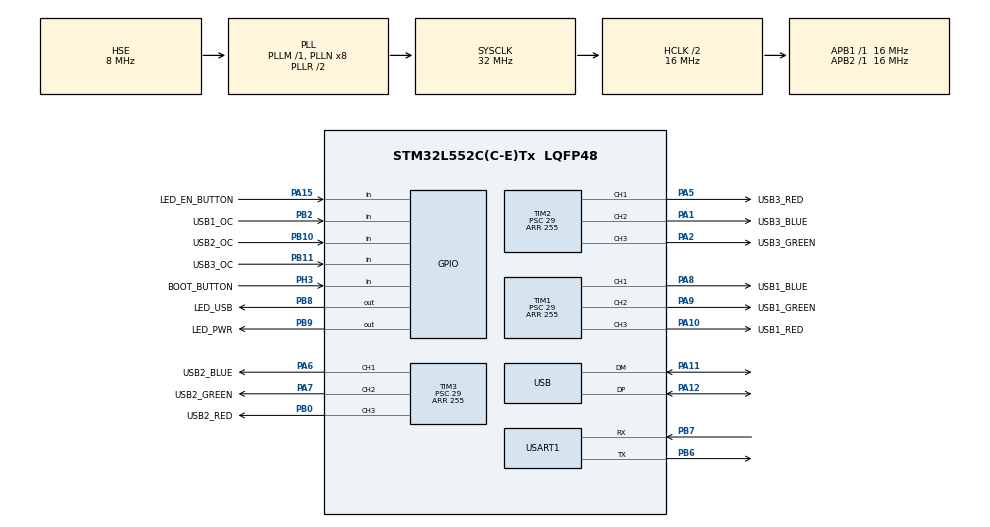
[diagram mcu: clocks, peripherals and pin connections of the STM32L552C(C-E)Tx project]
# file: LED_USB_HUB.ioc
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Mcu.Family=STM32L5
Mcu.Name=STM32L552C(C-E)Tx
Mcu.Package=LQFP48
NVIC.PriorityGroup=NVIC_PRIORITYGROUP_3
NVIC.TIM7_IRQn=true\:7\:0\:false\:false\:true\:false\:true\:true
NVIC.TimeBase=TIM7_IRQn
NVIC.TimeBaseIP=TIM7
PA1.GPIO_Label=USB3_BLUE
PA1.Signal=S_TIM2_CH2
PA10.GPIO_Label=USB1_RED
PA10.Signal=S_TIM1_CH3
PA11.Mode=Device
PA11.Signal=USB_DM
PA12.Mode=Device
PA12.Signal=USB_DP
PA13\ (JTMS/SWDIO).GPIO_Label=SWDIO
PA13\ (JTMS/SWDIO).Mode=Serial_Wire
PA13\ (JTMS/SWDIO).Signal=DEBUG_JTMS-SWDIO
PA14\ (JTCK/SWCLK).GPIO_Label=SWCLK
PA14\ (JTCK/SWCLK).Mode=Serial_Wire
PA14\ (JTCK/SWCLK).Signal=DEBUG_JTCK-SWCLK
PA15\ (JTDI).GPIO_Label=LED_EN_BUTTON
PA15\ (JTDI).Signal=GPIO_Input
PA2.GPIO_Label=USB3_GREEN
PA2.Signal=S_TIM2_CH3
PA5.GPIO_Label=USB3_RED
PA5.Signal=S_TIM2_CH1
PA6.GPIO_Label=USB2_BLUE
PA6.Signal=S_TIM3_CH1
PA7.GPIO_Label=USB2_GREEN
PA7.Signal=S_TIM3_CH2
PA8.GPIO_Label=USB1_BLUE
PA8.Signal=S_TIM1_CH1
PA9.GPIO_Label=USB1_GREEN
PA9.Signal=S_TIM1_CH2
PB0.GPIO_Label=USB2_RED
PB0.Signal=S_TIM3_CH3
PB10.GPIO_Label=USB2_OC
PB10.Signal=GPIO_Input
PB11.GPIO_Label=USB3_OC
PB11.Signal=GPIO_Input
PB2.GPIO_Label=USB1_OC
PB2.Signal=GPIO_Input
PB6.Mode=Asynchronous
PB6.Signal=USART1_TX
PB7.Mode=Asynchronous
PB7.Signal=USART1_RX
PB8.GPIO_Label=LED_USB
PB8.PinState=GPIO_PIN_SET
PB8.Signal=GPIO_Output
PB9.GPIO_Label=LED_PWR
PB9.PinState=GPIO_PIN_SET
PB9.Signal=GPIO_Output
PH0-OSC_IN\ (PH0).GPIO_Label=HSI_IN
PH0-OSC_IN\ (PH0).Mode=HSE-External-Oscillator
PH0-OSC_IN\ (PH0).Signal=RCC_OSC_IN
PH1-OSC_OUT\ (PH1).GPIO_Label=HSI_OUT
PH1-OSC_OUT\ (PH1).Mode=HSE-External-Oscillator
PH1-OSC_OUT\ (PH1).Signal=RCC_OSC_OUT
PH3-BOOT0.GPIO_Label=BOOT_BUTTON
PH3-BOOT0.Signal=GPIO_Input
ProjectManager.HeapSize=0x200
ProjectManager.StackSize=0x400
ProjectManager.TargetToolchain=STM32CubeIDE
RCC.ADCFreq_Value=48000000
RCC.AHBCLKDivider=RCC_SYSCLK_DIV2
RCC.AHBFreq_Value=16000000
RCC.APB1Freq_Value=16000000
RCC.APB1TimFreq_Value=16000000
RCC.APB2Freq_Value=16000000
RCC.APB2TimFreq_Value=16000000
RCC.CortexFreq_Value=16000000
RCC.HCLKFreq_Value=16000000
RCC.HSE_VALUE=8000000
RCC.HSI48_VALUE=48000000
RCC.HSI_VALUE=16000000
RCC.LSE_VALUE=32768
RCC.MSI_VALUE=4000000
RCC.PLLSAI1M=2
RCC.PLLSAI1N=24
RCC.PLLSAI1Source=RCC_PLLSAI1SOURCE_HSE
RCC.PLLSAI2Source=RCC_PLLSAI2SOURCE_HSE
RCC.PLLSourceVirtual=RCC_PLLSOURCE_HSE
RCC.SYSCLKFreq_VALUE=32000000
RCC.SYSCLKSource=RCC_SYSCLKSOURCE_PLLCLK
RCC.USART1CLockSelectionVirtual=RCC_USART1CLKSOURCE_SYSCLK
RCC.USBFreq_Value=48000000
RCC.VCOOutputFreq_Value=64000000
SH.S_TIM1_CH1.0=TIM1_CH1,PWM Generation1 CH1
SH.S_TIM1_CH2.0=TIM1_CH2,PWM Generation2 CH2
SH.S_TIM1_CH3.0=TIM1_CH3,PWM Generation3 CH3
SH.S_TIM2_CH1.0=TIM2_CH1,PWM Generation1 CH1
SH.S_TIM2_CH2.0=TIM2_CH2,PWM Generation2 CH2
SH.S_TIM2_CH3.0=TIM2_CH3,PWM Generation3 CH3
SH.S_TIM3_CH1.0=TIM3_CH1,PWM Generation1 CH1
SH.S_TIM3_CH2.0=TIM3_CH2,PWM Generation2 CH2
SH.S_TIM3_CH3.0=TIM3_CH3,PWM Generation3 CH3
TIM1.Channel-PWM\ Generation1\ CH1=TIM_CHANNEL_1
TIM1.Channel-PWM\ Generation2\ CH2=TIM_CHANNEL_2
TIM1.Channel-PWM\ Generation3\ CH3=TIM_CHANNEL_3
TIM1.OCIdleState_1=TIM_OCIDLESTATE_RESET
TIM1.OCIdleState_2=TIM_OCIDLESTATE_RESET
TIM1.OCIdleState_3=TIM_OCIDLESTATE_RESET
TIM1.OCPolarity_1=TIM_OCPOLARITY_LOW
TIM1.OCPolarity_2=TIM_OCPOLARITY_LOW
TIM1.OCPolarity_3=TIM_OCPOLARITY_LOW
TIM1.Period=255
TIM1.Prescaler=29
TIM2.Channel-PWM\ Generation1\ CH1=TIM_CHANNEL_1
TIM2.Channel-PWM\ Generation2\ CH2=TIM_CHANNEL_2
TIM2.Channel-PWM\ Generation3\ CH3=TIM_CHANNEL_3
TIM2.OCPolarity_1=TIM_OCPOLARITY_LOW
TIM2.OCPolarity_2=TIM_OCPOLARITY_LOW
TIM2.OCPolarity_3=TIM_OCPOLARITY_LOW
TIM2.Period=255
TIM2.Prescaler=29
TIM3.Channel-PWM\ Generation1\ CH1=TIM_CHANNEL_1
TIM3.Channel-PWM\ Generation2\ CH2=TIM_CHANNEL_2
TIM3.Channel-PWM\ Generation3\ CH3=TIM_CHANNEL_3
TIM3.OCPolarity_1=TIM_OCPOLARITY_LOW
TIM3.OCPolarity_2=TIM_OCPOLARITY_LOW
TIM3.OCPolarity_3=TIM_OCPOLARITY_LOW
TIM3.Period=255
TIM3.Prescaler=29
USART1.VirtualMode-Asynchronous=VM_ASYNC
VP_ICACHE_VS_ICACHE.Mode=DirectMappedCache
VP_PWR_VS_DBSignals.Mode=DisableDeadBatterySignals
VP_PWR_VS_SECSignals.Mode=Security/Privilege
VP_SYS_VS_tim7.Mode=TIM7
VP_TIM1_VS_ClockSourceINT.Mode=Internal
VP_TIM2_VS_ClockSourceINT.Mode=Internal
VP_TIM3_VS_ClockSourceINT.Mode=Internal
board=custom

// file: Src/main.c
/* USER CODE BEGIN Header */
/**
  ******************************************************************************
  * @file           : main.c
  * @brief          : Main program body
  ******************************************************************************
  * @attention
  *
  * Copyright (c) 2025 STMicroelectronics.
  * All rights reserved.
  *
  * This software is licensed under terms that can be found in the LICENSE file
  * in the root directory of this software component.
  * If no LICENSE file comes with this software, it is provided AS-IS.
  *
  ******************************************************************************
  */
/* USER CODE END Header */
#include "main.h"
#include "RGB_USB_HUB.h"

TIM_HandleTypeDef htim1;
TIM_HandleTypeDef htim2;
TIM_HandleTypeDef htim3;

UART_HandleTypeDef huart1;

PCD_HandleTypeDef hpcd_USB_FS;

void SystemClock_Config(void);
static void MX_GPIO_Init(void);
static void MX_TIM1_Init(void);
static void MX_TIM2_Init(void);
static void MX_TIM3_Init(void);
static void MX_USART1_UART_Init(void);
static void MX_USB_PCD_Init(void);
static void MX_ICACHE_Init(void);

int main(void)
{

  /* MCU Configuration--------------------------------------------------------*/

  /* Reset of all peripherals, Initializes the Flash interface and the Systick. */
  HAL_Init();

  /* Configure the system clock */
  SystemClock_Config();

  /* Initialize all configured peripherals */
  MX_GPIO_Init();
  MX_TIM1_Init();
  MX_TIM2_Init();
  MX_TIM3_Init();
  MX_USART1_UART_Init();
  MX_USB_PCD_Init();
  MX_ICACHE_Init();
  /* USER CODE BEGIN 2 */
  HUB_Init(&htim1, &htim2, &htim3, &hpcd_USB_FS);
  /* USER CODE END 2 */

  /* Infinite loop */
  while (1)
  {

  }
}

void SystemClock_Config(void)
{
  RCC_OscInitTypeDef RCC_OscInitStruct = {0};
  RCC_ClkInitTypeDef RCC_ClkInitStruct = {0};

  /** Configure the main internal regulator output voltage
  */
  if (HAL_PWREx_ControlVoltageScaling(PWR_REGULATOR_VOLTAGE_SCALE2) != HAL_OK)
  {
    Error_Handler();
  }

  /** Initializes the RCC Oscillators according to the specified parameters
  * in the RCC_OscInitTypeDef structure.
  */
  RCC_OscInitStruct.OscillatorType = RCC_OSCILLATORTYPE_HSE;
  RCC_OscInitStruct.HSEState = RCC_HSE_ON;
  RCC_OscInitStruct.PLL.PLLState = RCC_PLL_ON;
  RCC_OscInitStruct.PLL.PLLSource = RCC_PLLSOURCE_HSE;
  RCC_OscInitStruct.PLL.PLLM = 1;
  RCC_OscInitStruct.PLL.PLLN = 8;
  RCC_OscInitStruct.PLL.PLLP = RCC_PLLP_DIV7;
  RCC_OscInitStruct.PLL.PLLQ = RCC_PLLQ_DIV2;
  RCC_OscInitStruct.PLL.PLLR = RCC_PLLR_DIV2;
  if (HAL_RCC_OscConfig(&RCC_OscInitStruct) != HAL_OK)
  {
    Error_Handler();
  }

  /** Initializes the CPU, AHB and APB buses clocks
  */
  RCC_ClkInitStruct.ClockType = RCC_CLOCKTYPE_HCLK|RCC_CLOCKTYPE_SYSCLK
                              |RCC_CLOCKTYPE_PCLK1|RCC_CLOCKTYPE_PCLK2;
  RCC_ClkInitStruct.SYSCLKSource = RCC_SYSCLKSOURCE_PLLCLK;
  RCC_ClkInitStruct.AHBCLKDivider = RCC_SYSCLK_DIV2;
  RCC_ClkInitStruct.APB1CLKDivider = RCC_HCLK_DIV1;
  RCC_ClkInitStruct.APB2CLKDivider = RCC_HCLK_DIV1;

  if (HAL_RCC_ClockConfig(&RCC_ClkInitStruct, FLASH_LATENCY_1) != HAL_OK)
  {
    Error_Handler();
  }
}

static void MX_ICACHE_Init(void)
{

  /** Enable instruction cache in 1-way (direct mapped cache)
  */
  if (HAL_ICACHE_ConfigAssociativityMode(ICACHE_1WAY) != HAL_OK)
  {
    Error_Handler();
  }
  if (HAL_ICACHE_Enable() != HAL_OK)
  {
    Error_Handler();
  }

}

static void MX_TIM1_Init(void)
{

  TIM_ClockConfigTypeDef sClockSourceConfig = {0};
  TIM_MasterConfigTypeDef sMasterConfig = {0};
  TIM_OC_InitTypeDef sConfigOC = {0};
  TIM_BreakDeadTimeConfigTypeDef sBreakDeadTimeConfig = {0};

  htim1.Instance = TIM1;
  htim1.Init.Prescaler = 29;
  htim1.Init.CounterMode = TIM_COUNTERMODE_UP;
  htim1.Init.Period = 255;
  htim1.Init.ClockDivision = TIM_CLOCKDIVISION_DIV1;
  htim1.Init.RepetitionCounter = 0;
  htim1.Init.AutoReloadPreload = TIM_AUTORELOAD_PRELOAD_DISABLE;
  if (HAL_TIM_Base_Init(&htim1) != HAL_OK)
  {
    Error_Handler();
  }
  sClockSourceConfig.ClockSource = TIM_CLOCKSOURCE_INTERNAL;
  if (HAL_TIM_ConfigClockSource(&htim1, &sClockSourceConfig) != HAL_OK)
  {
    Error_Handler();
  }
  if (HAL_TIM_PWM_Init(&htim1) != HAL_OK)
  {
    Error_Handler();
  }
  sMasterConfig.MasterOutputTrigger = TIM_TRGO_RESET;
  sMasterConfig.MasterOutputTrigger2 = TIM_TRGO2_RESET;
  sMasterConfig.MasterSlaveMode = TIM_MASTERSLAVEMODE_DISABLE;
  if (HAL_TIMEx_MasterConfigSynchronization(&htim1, &sMasterConfig) != HAL_OK)
  {
    Error_Handler();
  }
  sConfigOC.OCMode = TIM_OCMODE_PWM1;
  sConfigOC.Pulse = 0;
  sConfigOC.OCPolarity = TIM_OCPOLARITY_LOW;
  sConfigOC.OCNPolarity = TIM_OCNPOLARITY_HIGH;
  sConfigOC.OCFastMode = TIM_OCFAST_DISABLE;
  sConfigOC.OCIdleState = TIM_OCIDLESTATE_RESET;
  sConfigOC.OCNIdleState = TIM_OCNIDLESTATE_RESET;
  if (HAL_TIM_PWM_ConfigChannel(&htim1, &sConfigOC, TIM_CHANNEL_1) != HAL_OK)
  {
    Error_Handler();
  }
  if (HAL_TIM_PWM_ConfigChannel(&htim1, &sConfigOC, TIM_CHANNEL_2) != HAL_OK)
  {
    Error_Handler();
  }
  if (HAL_TIM_PWM_ConfigChannel(&htim1, &sConfigOC, TIM_CHANNEL_3) != HAL_OK)
  {
    Error_Handler();
  }
  sBreakDeadTimeConfig.OffStateRunMode = TIM_OSSR_DISABLE;
  sBreakDeadTimeConfig.OffStateIDLEMode = TIM_OSSI_DISABLE;
  sBreakDeadTimeConfig.LockLevel = TIM_LOCKLEVEL_OFF;
  sBreakDeadTimeConfig.DeadTime = 0;
  sBreakDeadTimeConfig.BreakState = TIM_BREAK_DISABLE;
  sBreakDeadTimeConfig.BreakPolarity = TIM_BREAKPOLARITY_HIGH;
  sBreakDeadTimeConfig.BreakFilter = 0;
  sBreakDeadTimeConfig.BreakAFMode = TIM_BREAK_AFMODE_INPUT;
  sBreakDeadTimeConfig.Break2State = TIM_BREAK2_DISABLE;
  sBreakDeadTimeConfig.Break2Polarity = TIM_BREAK2POLARITY_HIGH;
  sBreakDeadTimeConfig.Break2Filter = 0;
  sBreakDeadTimeConfig.Break2AFMode = TIM_BREAK_AFMODE_INPUT;
  sBreakDeadTimeConfig.AutomaticOutput = TIM_AUTOMATICOUTPUT_DISABLE;
  if (HAL_TIMEx_ConfigBreakDeadTime(&htim1, &sBreakDeadTimeConfig) != HAL_OK)
  {
    Error_Handler();
  }
  HAL_TIM_MspPostInit(&htim1);

}

static void MX_TIM2_Init(void)
{

  TIM_ClockConfigTypeDef sClockSourceConfig = {0};
  TIM_MasterConfigTypeDef sMasterConfig = {0};
  TIM_OC_InitTypeDef sConfigOC = {0};

  htim2.Instance = TIM2;
  htim2.Init.Prescaler = 29;
  htim2.Init.CounterMode = TIM_COUNTERMODE_UP;
  htim2.Init.Period = 255;
  htim2.Init.ClockDivision = TIM_CLOCKDIVISION_DIV1;
  htim2.Init.AutoReloadPreload = TIM_AUTORELOAD_PRELOAD_DISABLE;
  if (HAL_TIM_Base_Init(&htim2) != HAL_OK)
  {
    Error_Handler();
  }
  sClockSourceConfig.ClockSource = TIM_CLOCKSOURCE_INTERNAL;
  if (HAL_TIM_ConfigClockSource(&htim2, &sClockSourceConfig) != HAL_OK)
  {
    Error_Handler();
  }
  if (HAL_TIM_PWM_Init(&htim2) != HAL_OK)
  {
    Error_Handler();
  }
  sMasterConfig.MasterOutputTrigger = TIM_TRGO_RESET;
  sMasterConfig.MasterSlaveMode = TIM_MASTERSLAVEMODE_DISABLE;
  if (HAL_TIMEx_MasterConfigSynchronization(&htim2, &sMasterConfig) != HAL_OK)
  {
    Error_Handler();
  }
  sConfigOC.OCMode = TIM_OCMODE_PWM1;
  sConfigOC.Pulse = 0;
  sConfigOC.OCPolarity = TIM_OCPOLARITY_LOW;
  sConfigOC.OCFastMode = TIM_OCFAST_DISABLE;
  if (HAL_TIM_PWM_ConfigChannel(&htim2, &sConfigOC, TIM_CHANNEL_1) != HAL_OK)
  {
    Error_Handler();
  }
  if (HAL_TIM_PWM_ConfigChannel(&htim2, &sConfigOC, TIM_CHANNEL_2) != HAL_OK)
  {
    Error_Handler();
  }
  if (HAL_TIM_PWM_ConfigChannel(&htim2, &sConfigOC, TIM_CHANNEL_3) != HAL_OK)
  {
    Error_Handler();
  }
  HAL_TIM_MspPostInit(&htim2);

}

static void MX_TIM3_Init(void)
{

  TIM_ClockConfigTypeDef sClockSourceConfig = {0};
  TIM_MasterConfigTypeDef sMasterConfig = {0};
  TIM_OC_InitTypeDef sConfigOC = {0};

  htim3.Instance = TIM3;
  htim3.Init.Prescaler = 29;
  htim3.Init.CounterMode = TIM_COUNTERMODE_UP;
  htim3.Init.Period = 255;
  htim3.Init.ClockDivision = TIM_CLOCKDIVISION_DIV1;
  htim3.Init.AutoReloadPreload = TIM_AUTORELOAD_PRELOAD_DISABLE;
  if (HAL_TIM_Base_Init(&htim3) != HAL_OK)
  {
    Error_Handler();
  }
  sClockSourceConfig.ClockSource = TIM_CLOCKSOURCE_INTERNAL;
  if (HAL_TIM_ConfigClockSource(&htim3, &sClockSourceConfig) != HAL_OK)
  {
    Error_Handler();
  }
  if (HAL_TIM_PWM_Init(&htim3) != HAL_OK)
  {
    Error_Handler();
  }
  sMasterConfig.MasterOutputTrigger = TIM_TRGO_RESET;
  sMasterConfig.MasterSlaveMode = TIM_MASTERSLAVEMODE_DISABLE;
  if (HAL_TIMEx_MasterConfigSynchronization(&htim3, &sMasterConfig) != HAL_OK)
  {
    Error_Handler();
  }
  sConfigOC.OCMode = TIM_OCMODE_PWM1;
  sConfigOC.Pulse = 0;
  sConfigOC.OCPolarity = TIM_OCPOLARITY_LOW;
  sConfigOC.OCFastMode = TIM_OCFAST_DISABLE;
  if (HAL_TIM_PWM_ConfigChannel(&htim3, &sConfigOC, TIM_CHANNEL_1) != HAL_OK)
  {
    Error_Handler();
  }
  if (HAL_TIM_PWM_ConfigChannel(&htim3, &sConfigOC, TIM_CHANNEL_2) != HAL_OK)
  {
    Error_Handler();
  }
  if (HAL_TIM_PWM_ConfigChannel(&htim3, &sConfigOC, TIM_CHANNEL_3) != HAL_OK)
  {
    Error_Handler();
  }
  HAL_TIM_MspPostInit(&htim3);

}

static void MX_USART1_UART_Init(void)
{

  huart1.Instance = USART1;
  huart1.Init.BaudRate = 115200;
  huart1.Init.WordLength = UART_WORDLENGTH_8B;
  huart1.Init.StopBits = UART_STOPBITS_1;
  huart1.Init.Parity = UART_PARITY_NONE;
  huart1.Init.Mode = UART_MODE_TX_RX;
  huart1.Init.HwFlowCtl = UART_HWCONTROL_NONE;
  huart1.Init.OverSampling = UART_OVERSAMPLING_16;
  huart1.Init.OneBitSampling = UART_ONE_BIT_SAMPLE_DISABLE;
  huart1.Init.ClockPrescaler = UART_PRESCALER_DIV1;
  huart1.AdvancedInit.AdvFeatureInit = UART_ADVFEATURE_NO_INIT;
  if (HAL_UART_Init(&huart1) != HAL_OK)
  {
    Error_Handler();
  }
  if (HAL_UARTEx_SetTxFifoThreshold(&huart1, UART_TXFIFO_THRESHOLD_1_8) != HAL_OK)
  {
    Error_Handler();
  }
  if (HAL_UARTEx_SetRxFifoThreshold(&huart1, UART_RXFIFO_THRESHOLD_1_8) != HAL_OK)
  {
    Error_Handler();
  }
  if (HAL_UARTEx_DisableFifoMode(&huart1) != HAL_OK)
  {
    Error_Handler();
  }

}

static void MX_USB_PCD_Init(void)
{

  hpcd_USB_FS.Instance = USB;
  hpcd_USB_FS.Init.dev_endpoints = 8;
  hpcd_USB_FS.Init.speed = PCD_SPEED_FULL;
  hpcd_USB_FS.Init.phy_itface = PCD_PHY_EMBEDDED;
  hpcd_USB_FS.Init.Sof_enable = DISABLE;
  hpcd_USB_FS.Init.low_power_enable = DISABLE;
  hpcd_USB_FS.Init.lpm_enable = DISABLE;
  hpcd_USB_FS.Init.battery_charging_enable = DISABLE;
  if (HAL_PCD_Init(&hpcd_USB_FS) != HAL_OK)
  {
    Error_Handler();
  }

}

static void MX_GPIO_Init(void)
{
  GPIO_InitTypeDef GPIO_InitStruct = {0};

  /* GPIO Ports Clock Enable */
  __HAL_RCC_GPIOC_CLK_ENABLE();
  __HAL_RCC_GPIOH_CLK_ENABLE();
  __HAL_RCC_GPIOA_CLK_ENABLE();
  __HAL_RCC_GPIOB_CLK_ENABLE();

  /*Configure GPIO pin Output Level */
  HAL_GPIO_WritePin(GPIOB, LED_USB_Pin|LED_PWR_Pin, GPIO_PIN_SET);

  /*Configure GPIO pins : PC13 PC14 PC15 */
  GPIO_InitStruct.Pin = GPIO_PIN_13|GPIO_PIN_14|GPIO_PIN_15;
  GPIO_InitStruct.Mode = GPIO_MODE_ANALOG;
  GPIO_InitStruct.Pull = GPIO_NOPULL;
  HAL_GPIO_Init(GPIOC, &GPIO_InitStruct);

  /*Configure GPIO pins : PA0 PA3 PA4 */
  GPIO_InitStruct.Pin = GPIO_PIN_0|GPIO_PIN_3|GPIO_PIN_4;
  GPIO_InitStruct.Mode = GPIO_MODE_ANALOG;
  GPIO_InitStruct.Pull = GPIO_NOPULL;
  HAL_GPIO_Init(GPIOA, &GPIO_InitStruct);

  /*Configure GPIO pins : PB1 PB12 PB13 PB14
                           PB15 PB3 PB4 PB5 */
  GPIO_InitStruct.Pin = GPIO_PIN_1|GPIO_PIN_12|GPIO_PIN_13|GPIO_PIN_14
                          |GPIO_PIN_15|GPIO_PIN_3|GPIO_PIN_4|GPIO_PIN_5;
  GPIO_InitStruct.Mode = GPIO_MODE_ANALOG;
  GPIO_InitStruct.Pull = GPIO_NOPULL;
  HAL_GPIO_Init(GPIOB, &GPIO_InitStruct);

  /*Configure GPIO pins : USB1_OC_Pin USB2_OC_Pin USB3_OC_Pin */
  GPIO_InitStruct.Pin = USB1_OC_Pin|USB2_OC_Pin|USB3_OC_Pin;
  GPIO_InitStruct.Mode = GPIO_MODE_INPUT;
  GPIO_InitStruct.Pull = GPIO_NOPULL;
  HAL_GPIO_Init(GPIOB, &GPIO_InitStruct);

  /*Configure GPIO pin : LED_EN_BUTTON_Pin */
  GPIO_InitStruct.Pin = LED_EN_BUTTON_Pin;
  GPIO_InitStruct.Mode = GPIO_MODE_INPUT;
  GPIO_InitStruct.Pull = GPIO_NOPULL;
  HAL_GPIO_Init(LED_EN_BUTTON_GPIO_Port, &GPIO_InitStruct);

  /*Configure GPIO pin : BOOT_BUTTON_Pin */
  GPIO_InitStruct.Pin = BOOT_BUTTON_Pin;
  GPIO_InitStruct.Mode = GPIO_MODE_INPUT;
  GPIO_InitStruct.Pull = GPIO_NOPULL;
  HAL_GPIO_Init(BOOT_BUTTON_GPIO_Port, &GPIO_InitStruct);

  /*Configure GPIO pins : LED_USB_Pin LED_PWR_Pin */
  GPIO_InitStruct.Pin = LED_USB_Pin|LED_PWR_Pin;
  GPIO_InitStruct.Mode = GPIO_MODE_OUTPUT_PP;
  GPIO_InitStruct.Pull = GPIO_NOPULL;
  GPIO_InitStruct.Speed = GPIO_SPEED_FREQ_LOW;
  HAL_GPIO_Init(GPIOB, &GPIO_InitStruct);

}

void HAL_TIM_PeriodElapsedCallback(TIM_HandleTypeDef *htim)
{
  if (htim->Instance == TIM7)
  {
    HAL_IncTick();
  }
  /* USER CODE BEGIN Callback 1 */
  else if (htim->Instance == TIM7) {
	  // Piggyback on TIM7 1ms updates to trigger the task calls
	  HUB_Task();
  }
  /* USER CODE END Callback 1 */
}

void Error_Handler(void)
{
  __disable_irq();
  while (1)
  {
  }
}
